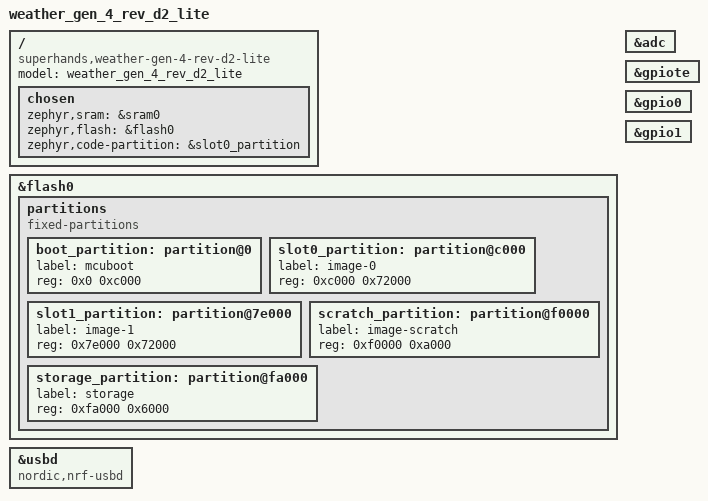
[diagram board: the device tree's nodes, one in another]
// Copyright (c) 2023 Nordic Semiconductor ASA
// SPDX-License-Identifier: Apache-2.0

/dts-v1/;
#include <nordic/nrf52840_qiaa.dtsi>
// #include "nrf52840dongle_nrf52840-pinctrl.dtsi"

/ {
	model = "weather_gen_4_rev_d2_lite";
	compatible = "superhands,weather-gen-4-rev-d2-lite";

	chosen {
		zephyr,sram = &sram0;
		zephyr,flash = &flash0;
		zephyr,code-partition = &slot0_partition;
		// zephyr,console = &cdc_acm_uart0;
        // zephyr,shell-uart = &cdc_acm_uart0;
	};
};

&flash0 {
	partitions {
		compatible = "fixed-partitions";
		#address-cells = <1>;
		#size-cells = <1>;

		boot_partition: partition@0 {
			label = "mcuboot";
			reg = <0x0 0xc000>;
		};
		slot0_partition: partition@c000 {
			label = "image-0";
			reg = <0xc000 0x72000>;
		};
		slot1_partition: partition@7e000 {
			label = "image-1";
			reg = <0x7e000 0x72000>;
		};
		scratch_partition: partition@f0000 {
			label = "image-scratch";
			reg = <0xf0000 0xa000>;
		};
		storage_partition: partition@fa000 {
			label = "storage";
			reg = <0xfa000 0x6000>;
		};
	};
};

&adc {
	status = "okay";
};

&gpiote {
	status = "okay";
};

&gpio0 {
	status = "okay";
};

&gpio1 {
	status = "okay";
};

// &uart0 {
// 	compatible = "nordic,nrf-uarte";
// 	status = "okay";
// 	current-speed = <115200>;
// 	// pinctrl-0 = <&uart0_default>;
// 	// pinctrl-1 = <&uart0_sleep>;
// 	// pinctrl-names = "default", "sleep";
// };

// &uart0 {
//     compatible = "zephyr,cdc-acm-uart";
//     status = "okay";
// };

zephyr_udc0: &usbd {
	compatible = "nordic,nrf-usbd";
	status = "okay";
};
